# AT32F423 register map
Vendor: Keil; Series: AT32F423; File version: 1.0
CPU: CM4 r0p1, little endian, no MPU, FPU, 4 interrupt priority bits
Registers are 32-bit, read-write, reset 0x0 unless marked. A register's access mark holds for its fields unless they carry their own. Offsets are from the block's base; [hi:lo] are bit positions.

## ACC — HICK Auto Clock Calibration
Base 0x40017400
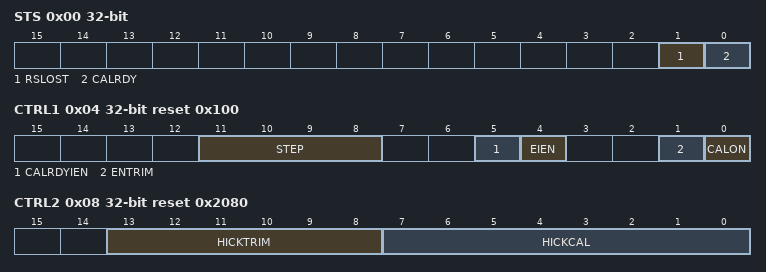
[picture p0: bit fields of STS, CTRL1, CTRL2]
0x00 STS ro — status register
  [1] RSLOST rw — Reference Signal Lost
    0=NotLost (Reference Signal is not lost); 1=Lost (Reference Signal is lost)
  [0] CALRDY rw — Internal high-speed clock calibration ready
    0=NotReady (Interal 8MHz oscillator calibration is not ready); 1=Ready (Interal 8MHz oscillator calibration is ready)
0x04 CTRL1 reset 0x100 — control register 1
  [11:8] STEP — Calibrated step
  [5] CALRDYIEN — CALRDY interrupt enable
    on read: 0=Disabled (Interrupt generation disabled); 1=Enabled (ACC interrupt is generated when CALRDY=1 in the ACC_STS register) | on write: 0=Disable (Interrupt generation disabled); 1=Enable (ACC interrupt is generated when CALRDY=1 in the ACC_STS register)
  [4] EIEN — RSLOST error interrupt enable
    on read: 0=Disabled (Interrupt generation disabled); 1=Enabled (ACC interrupt is generated when RSLOST=1 in the ACC_STS register) | on write: 0=Disable (Interrupt generation disabled); 1=Enable (ACC interrupt is generated when RSLOST=1 in the ACC_STS register)
  [1] ENTRIM — Enable trim
    0=HICKCAL (HICKCAL is calibrated); 1=HICKTRIM (HICKTRIM is calibrated)
  [0] CALON — Calibration on
    on read: 0=Disabled (Calibration disabled); 1=Enabled (Calibration enabled, and starts searching for a pulse on the USB_SOF) | on write: 0=Disable (Calibration disabled); 1=Enable (Calibration enabled, and starts searching for a pulse on the USB_SOF)
0x08 CTRL2 reset 0x2080 — control register 2
  [13:8] HICKTRIM ro — Internal high-speed auto clock trimming
  [7:0] HICKCAL ro — Internal high-speed auto clock calibration
0x0C C1 reset 0x1F2C — compare value 1
  [15:0] C1 — Compare 1
0x10 C2 reset 0x1F40 — compare value 2
  [15:0] C2 — Compare 2
0x14 C3 reset 0x1F54 — compare value 3
  [15:0] C3 — Compare 3

## ADCCOM — ADC common area
Base 0x40012300
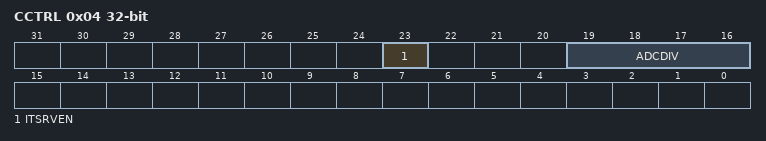
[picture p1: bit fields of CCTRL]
0x04 CCTRL — Common control register
  [23] ITSRVEN — Internal temperature sensor and VINTRV enable
  [19:16] ADCDIV — ADC division

## DAC — Digital to analog converter
Base 0x40007400
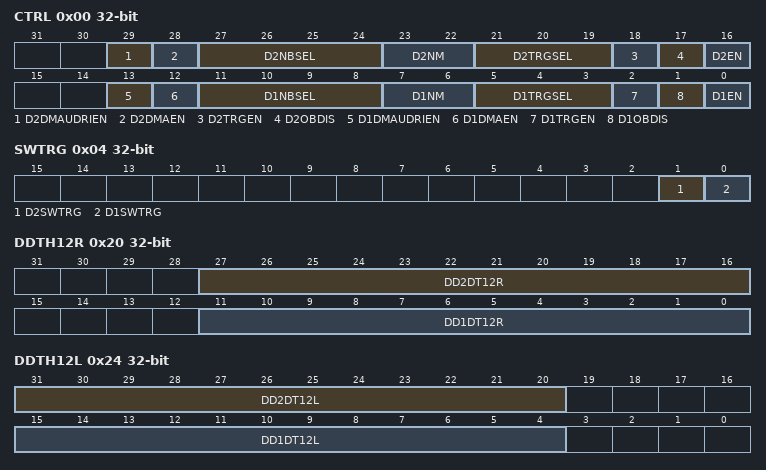
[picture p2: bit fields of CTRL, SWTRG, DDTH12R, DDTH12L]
0x00 CTRL — Control register (DAC_CTRL)
  [29] D2DMAUDRIEN — DAC2 DMA underrun interrupt enable
  [28] D2DMAEN — DAC2 DMA enable
  [27:24] D2NBSEL — DAC2 mask/amplitude selector
  [23:22] D2NM — DAC2 noise/triangle wave generation enable
  [21:19] D2TRGSEL — DAC2 trigger selection
  [18] D2TRGEN — DAC2 trigger enable
  [17] D2OBDIS — DAC2 output buffer disable
  [16] D2EN — DAC2 enable
  [13] D1DMAUDRIEN — DAC1 DMA underrun interrupt enable
  [12] D1DMAEN — DAC1 DMA enable
  [11:8] D1NBSEL — DAC1 mask/amplitude selector
  [7:6] D1NM — DAC1 noise/triangle wave generation enable
  [5:3] D1TRGSEL — DAC1 trigger selection
  [2] D1TRGEN — DAC1 trigger enable
  [1] D1OBDIS — DAC1 output buffer disable
  [0] D1EN — DAC1 enable
0x04 SWTRG wo — DAC software trigger register(DAC_SWTRIGR)
  [1] D2SWTRG — DAC2 software trigger
  [0] D1SWTRG — DAC1 software trigger
0x08 D1DTH12R — DAC1 12-bit right-aligned data holding register(DAC_D1DTH12R)
  [11:0] D1DT12R — DAC1 12-bit right-aligned data
0x0C D1DTH12L — DAC1 12-bit left aligned data holding register (DAC_D1DTH12L)
  [15:4] D1DT12L — DAC1 12-bit left-aligned data
0x10 D1DTH8R — DAC1 8-bit right aligned data holding register (DAC_D1DTH8R)
  [7:0] D1DT8R — DAC1 8-bit right-aligned data
0x14 D2DTH12R — DAC2 12-bit right aligned data holding register (DAC_D2DTH12R)
  [11:0] D2DT12R — DAC2 12-bit right-aligned data
0x18 D2DTH12L — DAC2 12-bit left aligned data holding register (DAC_D2DTH12L)
  [15:4] D2DT12L — DAC2 12-bit left-aligned data
0x1C D2DTH8R — DAC2 8-bit right-aligned data holding register (DAC_D2DTH8R)
  [7:0] D2DT8R — DAC2 8-bit right-aligned data
0x20 DDTH12R — Dual DAC 12-bit right-aligned data holding register (DAC_DDTH12R), Bits 31:28 Reserved, Bits 15:12 Reserved
  [27:16] DD2DT12R — DAC2 12-bit right-aligned data
  [11:0] DD1DT12R — DAC1 12-bit right-aligned data
0x24 DDTH12L — DUAL DAC 12-bit left aligned data holding register (DAC_DDTH12L), Bits 19:16 Reserved, Bits 3:0 Reserved
  [31:20] DD2DT12L — DAC2 12-bit right-aligned data
  [15:4] DD1DT12L — DAC1 12-bit left-aligned data
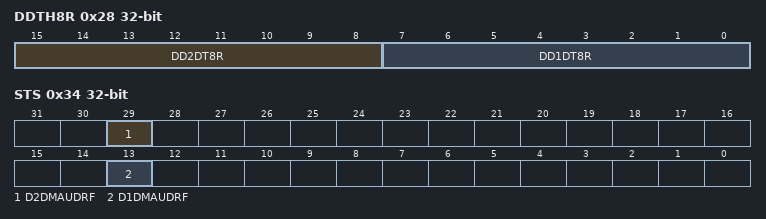
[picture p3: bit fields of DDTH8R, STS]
0x28 DDTH8R — DUAL DAC 8-bit right aligned data holding register (DAC_DDTH8R), Bits 31:16 Reserved
  [15:8] DD2DT8R — DAC2 8-bit right-aligned data
  [7:0] DD1DT8R — DAC1 8-bit right-aligned data
0x2C D1ODT ro — DAC1 data output register (DAC_D1ODT)
  [11:0] D1ODT — DAC1 data output
0x30 D2ODT ro — DAC2 data output register (DAC_D2ODT)
  [11:0] D2ODT — DAC2 data output
0x34 STS — DAC2 status register (DAC_STS)
  [29] D2DMAUDRF — DAC2 DMA underrun flag
  [13] D1DMAUDRF — DAC1 DMA underrun flag
